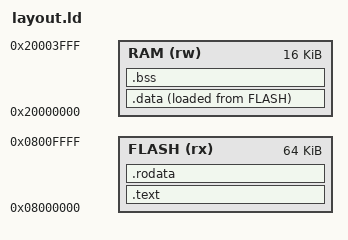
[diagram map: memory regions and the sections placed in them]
ENTRY(_start)
MEMORY {
    FLASH (rx) : ORIGIN = 0x08000000, LENGTH = 64K
    RAM (rw) : ORIGIN = 0x20000000, LENGTH = 16K
}
SECTIONS {
    .text : { *(.text*) } > FLASH
    .rodata : { *(.rodata*) } > FLASH
    .data : { *(.data*) } > RAM AT> FLASH
    .bss (NOLOAD) : { *(.bss*) *(COMMON) } > RAM
    /DISCARD/ : { *(.eh_frame*) *(.comment*) *(.note*) }
}
